AUTOSAR XML (schema 314)
package /ComponentType
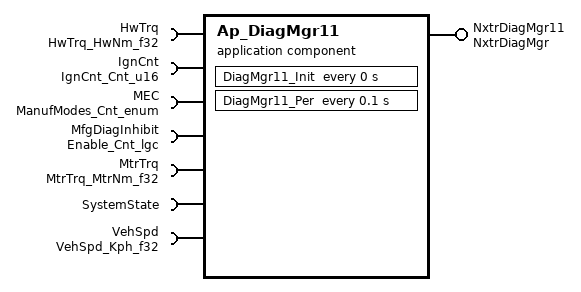
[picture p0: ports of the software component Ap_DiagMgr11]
  application software component type Ap_DiagMgr11
    provide port NxtrDiagMgr11: provided-interface=NxtrDiagMgr
      provided-com-specs:
        operation=GetNTCActive, queue-length=1
        operation=GetNTCFailed, queue-length=1
        operation=GetNTCStatus, queue-length=1
        operation=SetNTCStatus, queue-length=1
    7 x require port:
      HwTrq: unqueued-receiver-com-spec{data-element=HwNm_f32, init-value=D_ZERO_ULS_F32}, required-interface=HwTrq_HwNm_f32
      IgnCnt: unqueued-receiver-com-spec{data-element=Cnt_u16, init-value=D_ZERO_CNT_U16}, required-interface=IgnCnt_Cnt_u16
      MEC: unqueued-receiver-com-spec{data-element=Cnt_enum, init-value=D_MANUFMODEINIT_CNT_ENUM}, required-interface=ManufModes_Cnt_enum
      MfgDiagInhibit: unqueued-receiver-com-spec{data-element=Cnt_lgc, init-value=D_FALSE_CNT_LGC}, required-interface=Enable_Cnt_lgc
      MtrTrq: unqueued-receiver-com-spec{data-element=MtrNm_f32, init-value=D_ZERO_ULS_F32}, required-interface=MtrTrq_MtrNm_f32
      SystemState: required-interface=SystemState
      VehSpd: unqueued-receiver-com-spec{data-element=Kph_f32, init-value=D_ZERO_ULS_F32}, required-interface=VehSpd_Kph_f32
  internal behavior Ap_DiagMgr11_InternalBehavior: component=Ap_DiagMgr11
    timing event DiagMgr11_InitEvent: start-on-event=DiagMgr11_Init, period=0
    timing event TMT_DiagMgr11_Per: start-on-event=DiagMgr11_Per, period=0.1
    mode switch event MST_DiagMgr11_Trns_0: start-on-event=DiagMgr11_Trns, activation=EXIT, mode=SystemState.Mode.OFF
    4 x operation invoked event:
      OIT_NxtrDiagMgr11_GetNTCActive_NxtrDiagMgr11_GetNTCActive: start-on-event=NxtrDiagMgr11_GetNTCActive, operation=NxtrDiagMgr11.GetNTCActive
      OIT_NxtrDiagMgr11_GetNTCFailed_NxtrDiagMgr11_GetNTCFailed: start-on-event=NxtrDiagMgr11_GetNTCFailed, operation=NxtrDiagMgr11.GetNTCFailed
      OIT_NxtrDiagMgr11_GetNTCStatus_NxtrDiagMgr11_GetNTCStatus: start-on-event=NxtrDiagMgr11_GetNTCStatus, operation=NxtrDiagMgr11.GetNTCStatus
      OIT_NxtrDiagMgr11_SetNTCStatus_NxtrDiagMgr11_SetNTCStatus: start-on-event=NxtrDiagMgr11_SetNTCStatus, operation=NxtrDiagMgr11.SetNTCStatus
    port-api-options:
      enable-take-address=false, indirect-api=false, port=HwTrq
      enable-take-address=false, indirect-api=false, port=IgnCnt
      enable-take-address=false, indirect-api=false, port=MEC
      enable-take-address=false, indirect-api=false, port=MfgDiagInhibit
      enable-take-address=false, indirect-api=false, port=MtrTrq
      enable-take-address=false, indirect-api=false, port=NxtrDiagMgr11
      enable-take-address=false, indirect-api=false, port=SystemState
      enable-take-address=false, indirect-api=false, port=VehSpd
    7 x runnable:
      DiagMgr11_Init
      DiagMgr11_Per
      DiagMgr11_Trns
      NxtrDiagMgr11_GetNTCActive: can-be-invoked-concurrently=true
      NxtrDiagMgr11_GetNTCFailed: can-be-invoked-concurrently=true
      NxtrDiagMgr11_GetNTCStatus: can-be-invoked-concurrently=true
      NxtrDiagMgr11_SetNTCStatus: can-be-invoked-concurrently=true
        6 x data receive point:
          REC_HwTrq_HwNm_f32: data-element=HwTrq.HwNm_f32
          REC_IgnCnt_Cnt_u16: data-element=IgnCnt.Cnt_u16
          REC_MEC_Cnt_enum: data-element=MEC.Cnt_enum
          REC_MfgDiagInhibit_Cnt_lgc: data-element=MfgDiagInhibit.Cnt_lgc
          REC_MtrTrq_MtrNm_f32: data-element=MtrTrq.MtrNm_f32
          REC_VehSpd_Kph_f32: data-element=VehSpd.Kph_f32
  swc implementation Ap_DiagMgr11_Implementation: behavior=Ap_DiagMgr11_InternalBehavior
    code-descriptors:
      code Code: type=SRC
